# RFBI register map
Vendor: Texas Instruments
Peripheral module from a debugger description file (folder 66AK2G0x_66AK2G1x).
Registers are 32-bit, access per field, reset values left out (the file's numbers can be read two ways) unless marked. A register's access mark holds for its fields unless they carry their own. Offsets are as the file gives them; lines under a group give offsets from that group; [hi:lo] are bit positions; {n}, {i} and the like mark numbered series; 'fields as' and 'values as' point back to an identical list; <NAME> marks a mode.

## RFBI
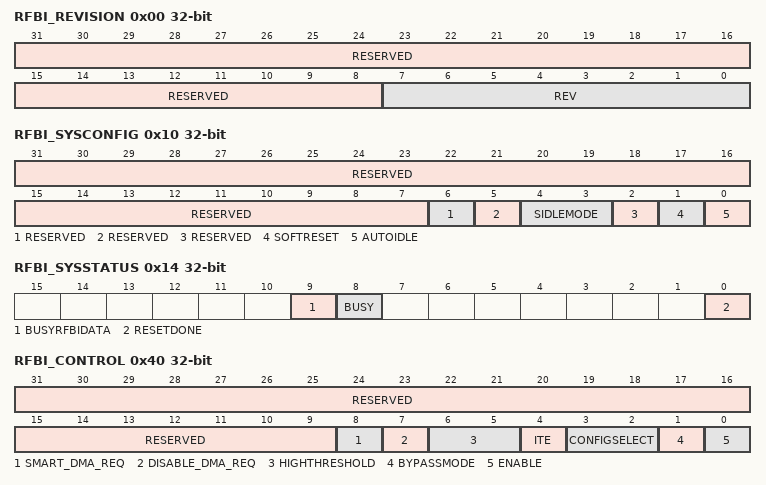
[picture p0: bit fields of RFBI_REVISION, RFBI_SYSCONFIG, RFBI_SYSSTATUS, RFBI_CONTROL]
0x00 RFBI_REVISION ro
  [31:8] RESERVED — Reads returns 0
  [7:0] REV — TI internal data. Identifies revision of peripheral.
0x10 RFBI_SYSCONFIG
  [31:7] RESERVED ro — Write 0's for future compatibility. Reads returns 0.
  [6] RESERVED ro — Write 0's for future compatibility. Reads returns 0.
  [5] RESERVED ro — Write 0's for future compatibility. Reads returns 0.
  [4:3] SIDLEMODE rw — Slave interface power management, Idle req/ack control. 0h (R/W) = Force-idle. An idle request is acknowledged unconditionally. 1h (R/W) = No-idle. An idle request is never acknowledged. 2h (R/W) = Smart-idle. Acknowledgement to an idle request is given based on the internal activity of the module.
  [2] RESERVED ro — Write 0's for future compatibility. Reads returns 0.
  [1] SOFTRESET rw — Software reset. Sets this bit to 1 to trigger a module reset. The bit is automatically reset by the hardware. During reads, it always returns 0. 0h (R/W) = Normal mode 1h (R/W) = The module is reset
  [0] AUTOIDLE rw — Internal clock gating strategy (OCP clock and display controller clock) 0h (R/W) = OCP clock and display controller clock are free-running 1h (R/W) = Automatic clock gating strategy is applied for the OCP clock and display controller clock, based on the OCP interface and internal activity.
0x14 RFBI_SYSSTATUS ro
  [9] BUSYRFBIDATA — Data are pending to be processed from internal FIFO. 0h (R) = No data pending 1h (R) = Some data are pending
  [8] BUSY — OCP Slave port busy status bit 0h (R) = The access to the following register is not stall: 1h (R) = The access to any of the following registers is stall:
  [0] RESETDONE — Internal reset monitoring. It can be used to determine when a HW reset is completed or when a SW reset is completed (software has set 0h (R) = Internal module reset is on-going 1h (R) = Reset completed
0x40 RFBI_CONTROL
  [31:9] RESERVED ro — Write 0's for future compatibility. Reads returns 0.
  [8] SMART_DMA_REQ rw — Smart DMA request 0h (R/W) = The dmareq is asserted and de-asserted depending on FIFO space even if MIdlereq is high in smart idle/no-idle mode and the entire burst gets error responses from the module. 1h (R/W) = The dmareq is de-asserted after 2 clk cycles if it has been asserted for more than or equal to 2 clk cycles and MIdlereq is high in smart idle or no idle mode. No more burst requests will be given even if the space is available in the FIFO.
  [7] DISABLE_DMA_REQ rw — Disable DMA request 0h (R/W) = The dmareq is enabled and the signal is generated based on the space available and the request coming into the data register 1h (R/W) = The dmareq is disabled and the signal is not generated at all based on space in FIFO. It stays high until the DISABLE DMAREQ is high even if there is space in FIFO to take requests
  [6:5] HIGHTHRESHOLD rw — Defines the FIFO high threshold used by HW to assert DMA request. Used only if data written to 0h (R/W) = Size of the transfer of 4 words of 32-bit wide 1h (R/W) = Size of the transfer of 8 words of 32-bit wide 2h (R/W) = Size of the transfer of 16 words of 32-bit wide
  [4] ITE rw — Internal Trigger 0h (R/W) = H/W waits for ITE bit to be set if in internal trigger mode for the configuration in use. 1h (R/W) = User sets the ITE bit to start the transfer, when H/W takes into account the bit, the H/W resets it.
  [3:2] CONFIGSELECT rw — Select the CS and configuration 0h (R/W) = No CS selected 1h (R/W) = CS0 selected and configuration #0 2h (R/W) = CS1 selected and configuration #1 3h (R/W) = CS0 and CS1 both selected (only the configuration for CS0 is used)
  [1] BYPASSMODE rw — Bypass Mode 0h (R/W) = The bypass mode not selected 1h (R/W) = The bypass mode is selected
  [0] ENABLE rw — Enable/Disable flag 0h (R/W) = Disable the RFBI module 1h (R/W) = Enable the RFBI module
0x44 RFBI_PIXEL_CNT rw
  [31:0] PIXELCNT — Pixel counter value. The SW indicates the number of pixels to transfer to the LCD panel frame buffer. The value is set when the module is disabled. During the transfer the HW decrements the register when a pixel has been sent to the RFB.
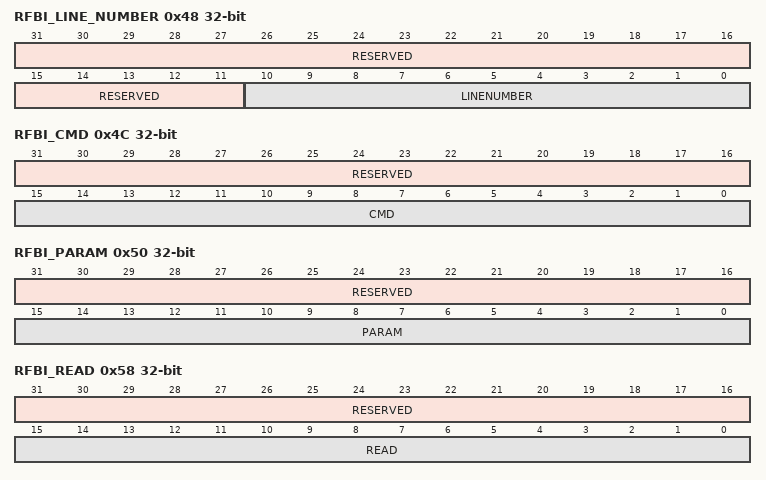
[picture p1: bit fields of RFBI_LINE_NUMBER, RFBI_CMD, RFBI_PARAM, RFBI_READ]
0x48 RFBI_LINE_NUMBER
  [31:11] RESERVED ro — Write 0's for future compatibility. Reads returns 0.
  [10:0] LINENUMBER rw — Programmable line number
0x4C RFBI_CMD
  [31:16] RESERVED ro — Write 0's for future compatibility. Reads returns 0.
  [15:0] CMD wo — Command Value. 8/9/12/16 bit value depending on the parallelMode. [7:0] 8-bit DataType [8:0] 9-bit DataType [11:0] 12-bit DataType [15:0] 16-bit DataType
0x50 RFBI_PARAM
  [31:16] RESERVED ro — Write 0's for future compatibility. Reads returns 0.
  [15:0] PARAM wo — Param Value. 8/9/12/16 bit value depending on the parallelMode. [7:0] 8-bit DataType [8:0] 9-bit DataType [11:0] 12-bit DataType [15:0] 16-bit DataType
0x54 RFBI_DATA wo
  [31:0] DATA — Data value. 12/16/18/24/2x16 bit value depending on the DataType. [11:0] 12-bit DataType [15:0] 16-bit DataType [17:0] 18-bit DataType [23:0] 24-bit DataType [31:0] 2x16-bit DataType
0x58 RFBI_READ
  [31:16] RESERVED ro — Write 0's for future compatibility. Reads returns 0.
  [15:0] READ rw — Read Value. 8/9/12/16 bit value depending on the parallelMode. [7:0] 8-bit DataType [8:0] 9-bit DataType [11:0] 12-bit DataType [15:0] 16-bit DataType
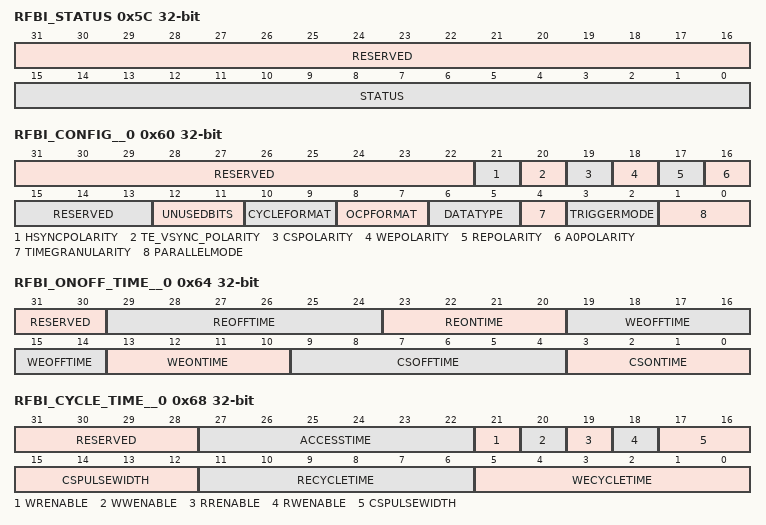
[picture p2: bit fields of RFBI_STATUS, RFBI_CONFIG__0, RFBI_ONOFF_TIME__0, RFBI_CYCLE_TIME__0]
0x5C RFBI_STATUS
  [31:16] RESERVED ro — Write 0's for future compatibility. Reads returns 0.
  [15:0] STATUS rw — Status value. 8/9/12/16 bit value depending on the parallelMode. [7:0] 8-bit DataType [8:0] 9-bit DataType [11:0] 12-bit DataType [15:0] 16-bit DataType
0x60 RFBI_CONFIG__0
  [31:22] RESERVED ro — Write 0's for future compatibility. Reads returns 0.
  [21] HSYNCPOLARITY rw — HSYNC polarity 0h (R/W) = HSYNC active low 1h (R/W) = HSYNC active high
  [20] TE_VSYNC_POLARITY rw — TE or VSYNC Polarity 0h (R/W) = active low 1h (R/W) = active high
  [19] CSPOLARITY rw — CS Polarity 0h (R/W) = CS active low 1h (R/W) = CS active high
  [18] WEPOLARITY rw — WE Polarity 0h (R/W) = active low 1h (R/W) = active high
  [17] REPOLARITY rw — RE Polarity 0h (R/W) = active low 1h (R/W) = active high
  [16] A0POLARITY rw — A0 Polarity 0h (R/W) = A0 active low 1h (R/W) = A0 active high
  [15:13] RESERVED ro — Write 0's for future compatibility. Reads returns 0.
  [12:11] UNUSEDBITS rw — State of unused bits 0h (R/W) = low level (0) 1h (R/W) = high level (1) 2h (R/W) = unchanged from previous state
  [10:9] CYCLEFORMAT rw — Cycle format 0h (R/W) = 1 cycle for 1 pixel 1h (R/W) = 2 cycles for 1 pixel 2h (R/W) = 3 cycles for 1 pixel 3h (R/W) = 3 cycles for 2 pixels
  [8:7] OCPFORMAT rw — OCP Write Access format 0h (R/W) = 1 pixel per OCP access to the register data 2h (R/W) = 2 pixels per OCP access to the register data with 1st pixel at the position [15:0] 3h (R/W) = 2 pixels per OCP access to the register data with 1st pixel at the position [31:16]
  [6:5] DATATYPE rw — Data type from the display controller and OCP slave port 0h (R/W) = 12-bit 1h (R/W) = 16-bit 2h (R/W) = 18-bit 3h (R/W) = 24-bit
  [4] TIMEGRANULARITY rw — Multiplies signal timing latencies by two 0h (R/W) = x2 latencies disabled 1h (R/W) = x2 latencies enabled
  [3:2] TRIGGERMODE rw — Trigger Mode 0h (R/W) = 00 Internal trigger mode ( 1h (R/W) = Tearing Effect Signal, RFBI_TEVSYNC0 is used with programmable line counter defined in 2h (R/W) = External trigger mode (RFBI_TEVSYNC/RFBI_HSYNC with programmable line counter defined in
  [1:0] PARALLELMODE rw — Parallel Mode 0h (R/W) = 8-bit parallel output interface selected 1h (R/W) = 9-bit parallel output interface selected 2h (R/W) = 12-bit parallel output interface selected 3h (R/W) = 16-bit parallel output interface selected
0x64 RFBI_ONOFF_TIME__0
  [31:30] RESERVED ro — Write 0's for future compatibility. Reads return 0.
  [29:24] REOFFTIME rw — Read Enable de-assertion time from start access time. Number of OCPClk cycles
  [23:20] REONTIME rw — Read Enable assertion time from start access time. Number of OCPClk cycles
  [19:14] WEOFFTIME rw — Write Enable de-assertion time from start access time. Number of OCPClk cycles
  [13:10] WEONTIME rw — Write Enable assertion time from start access time. Number of OCPClk cycles
  [9:4] CSOFFTIME rw — CS de-assertion time from start access time. Number of OCPClk cycles
  [3:0] CSONTIME rw — CS assertion time from start access time. Number of OCPClk cycles
0x68 RFBI_CYCLE_TIME__0
  [31:28] RESERVED ro — Write 0's for future compatibility. Reads return 0.
  [27:22] ACCESSTIME rw — Access Time. Number of OCPClk cycles.
  [21] WRENABLE rw — Write to Read Pulse Width Enable (same CS) 0h (R/W) = CSPulseWidth does not apply on Write to Read access 1h (R/W) = CSPulseWidth applies on Write to Read access
  [20] WWENABLE rw — Write to Write Pulse Width Enable (same CS) 0h (R/W) = CSPulseWidth does not apply on Write to Write access 1h (R/W) = CSPulseWidth applies on Write to Write access
  [19] RRENABLE rw — Read to Read Pulse Width Enable (same CS) 0h (R/W) = CSPulseWidth does not apply on Read to Read access 1h (R/W) = CSPulseWidth applies on Read to Read access
  [18] RWENABLE rw — Read to Write Pulse Width Enable (same CS). 0h (R/W) = CSPulseWidth does not apply on Read to Write access 1h (R/W) = CSPulseWidth applies on Read to Write access
  [17:12] CSPULSEWIDTH rw — CS Pulse Width. Number of OCPClk cycles.
  [11:6] RECYCLETIME rw — RE Cycle Time. Number of OCPClk cycles.
  [5:0] WECYCLETIME rw — WE Cycle Time. Number of OCPClk cycles.
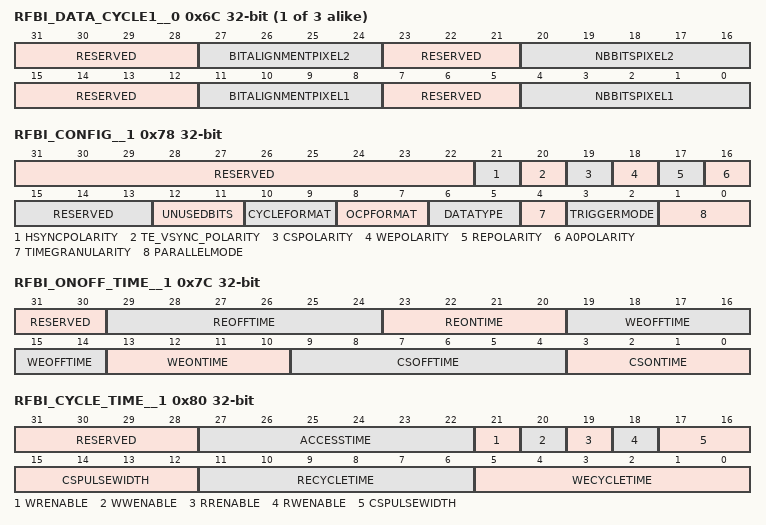
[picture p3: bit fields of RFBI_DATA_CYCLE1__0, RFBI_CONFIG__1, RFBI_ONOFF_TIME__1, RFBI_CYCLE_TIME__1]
{0x68+4i} RFBI_DATA_CYCLE{i}__0 (i=1..3)
  [31:28] RESERVED ro — Write 0's for future compatibility. Reads return 0.
  [27:24] BITALIGNMENTPIXEL2 rw — Bit alignment. Alignment of the bits from pixel#2 on the output interface.
  [23:21] RESERVED ro — Write 0's for future compatibility. Reads return 0.
  [20:16] NBBITSPIXEL2 rw — Number of bits. Number of bits from the pixel #2 (value from 0 to 16 bits). The values from 17 to 31 are invalid.
  [15:12] RESERVED ro — Write 0's for future compatibility. Reads return 0.
  [11:8] BITALIGNMENTPIXEL1 rw — Bit alignment. Alignment of the bits from pixel#1 on the output interface.
  [7:5] RESERVED ro — Write 0's for future compatibility. Reads return 0.
  [4:0] NBBITSPIXEL1 rw — Number of bits. Number of bits from the pixel #1 (value from 0 to 16 bits). The values from 17 to 31 are invalid.
0x78 RFBI_CONFIG__1
  [31:22] RESERVED ro — Write 0's for future compatibility Reads return 0
  [21] HSYNCPOLARITY rw — HSYNC polarity 0h (R/W) = HSYNC active low 1h (R/W) = HSYNC active high
  [20] TE_VSYNC_POLARITY rw — TE or VSYNC Polarity 0h (R/W) = active low 1h (R/W) = active high
  [19] CSPOLARITY rw — CS Polarity 0h (R/W) = CS active low 1h (R/W) = CS active high
  [18] WEPOLARITY rw — WE Polarity 0h (R/W) = active low 1h (R/W) = active high
  [17] REPOLARITY rw — RE Polarity 0h (R/W) = active low 1h (R/W) = active high
  [16] A0POLARITY rw — A0 Polarity 0h (R/W) = A0 active low 1h (R/W) = A0 active high
  [15:13] RESERVED ro — Write 0's for future compatibility. Reads return 0.
  [12:11] UNUSEDBITS rw — State of unused bits 0h (R/W) = low level (0) 1h (R/W) = high level (1) 2h (R/W) = unchanged from previous state
  [10:9] CYCLEFORMAT rw — Cycle format 0h (R/W) = 1 cycle for 1 pixel 1h (R/W) = 2 cycles for 1 pixel 2h (R/W) = 3 cycles for 1 pixel 3h (R/W) = 3 cycles for 2 pixels
  [8:7] OCPFORMAT rw — OCP Write Access format 0h (R/W) = 1 pixel per OCP access to the register data 2h (R/W) = 2 pixels per OCP access to the register data with 1st pixel at the position [15:0] 3h (R/W) = 2 pixels per OCP access to the register data with 1st pixel at the position [31:16]
  [6:5] DATATYPE rw — Data type from the display controller and OCP slave port 0h (R/W) = 12-bit 1h (R/W) = 16-bit 2h (R/W) = 18-bit 3h (R/W) = 24-bit
  [4] TIMEGRANULARITY rw — Multiplies signal timing latencies by two 0h (R/W) = x2 latencies disabled 1h (R/W) = x2 latencies enabled
  [3:2] TRIGGERMODE rw — Trigger Mode 0h (R/W) = 00 Internal trigger mode (ITE bit mode) 1h (R/W) = Tearing Effect Signal, RFBI_TE_VSYNC0 is used with programmable line counter defined in 2h (R/W) = External trigger mode (RFB_TE_VSYNC/RFB_HSYNC with programmable line counter defined in
  [1:0] PARALLELMODE rw — Parallel Mode 0h (R/W) = 8-bit parallel output interface selected 1h (R/W) = 9-bit parallel output interface selected 2h (R/W) = 12-bit parallel output interface selected 3h (R/W) = 16-bit parallel output interface selected
0x7C RFBI_ONOFF_TIME__1
  [31:30] RESERVED ro — Write 0's for future compatibility. Reads return 0.
  [29:24] REOFFTIME rw — Read Enable de-assertion time from start access time. Number of OCPClk cycles.
  [23:20] REONTIME rw — Read Enable assertion time from start access time. Number of OCPClk cycles.
  [19:14] WEOFFTIME rw — Write Enable de-assertion time from start access time. Number of OCPClk cycles.
  [13:10] WEONTIME rw — Write Enable assertion time from start access time. Number of OCPClk cycles.
  [9:4] CSOFFTIME rw — CS de-assertion time from start access time. Number of OCPClk cycles.
  [3:0] CSONTIME rw — CS assertion time from start access time. Number of OCPClk cycles.
0x80 RFBI_CYCLE_TIME__1
  [31:28] RESERVED ro — Write 0's for future compatibility. Reads return 0.
  [27:22] ACCESSTIME rw — Access Time. Number of OCPClk cycles
  [21] WRENABLE rw — Write to Read Pulse Width Enable (same CS) 0h (R/W) = CSPulseWidth does not apply on Write to Read access 1h (R/W) = CSPulseWidth applies on Write to Read access
  [20] WWENABLE rw — Write to Write Pulse Width Enable (same CS) 0h (R/W) = CSPulseWidth does not apply on Write to Write access 1h (R/W) = CSPulseWidth applies on Write to Write access
  [19] RRENABLE rw — Read to Read Pulse Width Enable (same CS) 0h (R/W) = CSPulseWidth does not apply on Read to Read access 1h (R/W) = CSPulseWidth applies on Read to Read access
  [18] RWENABLE rw — Read to Write Pulse Width Enable (same CS). 0h (R/W) = CSPulseWidth does not apply on Read to Write access 1h (R/W) = CSPulseWidth applies on Read to Write access
  [17:12] CSPULSEWIDTH rw — CS Pulse. Width Number of OCPClk cycles.
  [11:6] RECYCLETIME rw — RE Cycle. Time Number of OCPClk cycles.
  [5:0] WECYCLETIME rw — WE Cycle. Time Number of OCPClk cycles.
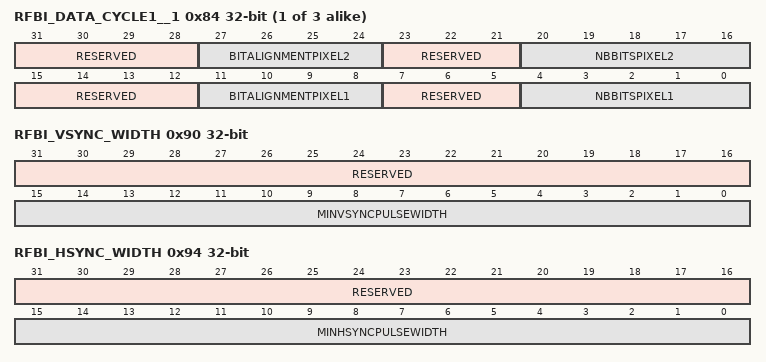
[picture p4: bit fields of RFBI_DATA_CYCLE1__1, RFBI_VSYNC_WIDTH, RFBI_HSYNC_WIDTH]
{0x80+4i} RFBI_DATA_CYCLE{i}__1 (i=1..3)
  fields as RFBI_DATA_CYCLE1__0
0x90 RFBI_VSYNC_WIDTH
  [31:16] RESERVED ro — Write 0's for future compatibility. Reads return 0.
  [15:0] MINVSYNCPULSEWIDTH rw — Programmable min VSYNC pulse width. Minimum VSYNC pulse width from 0 to 65535. Number of OCP clock cycles to determine when VSYNC pulse occurs. The values 0 and 1 are invalid.
0x94 RFBI_HSYNC_WIDTH
  [31:16] RESERVED ro — Write 0's for future compatibility. Reads return 0.
  [15:0] MINHSYNCPULSEWIDTH rw — Programmable min HSYNC pulse width. Minimum HSYNC pulse width from 0 to 65535. Number of OCP clock cycles to determine when HSYNC pulse occurs.The values 0 and 1 are invalid.
